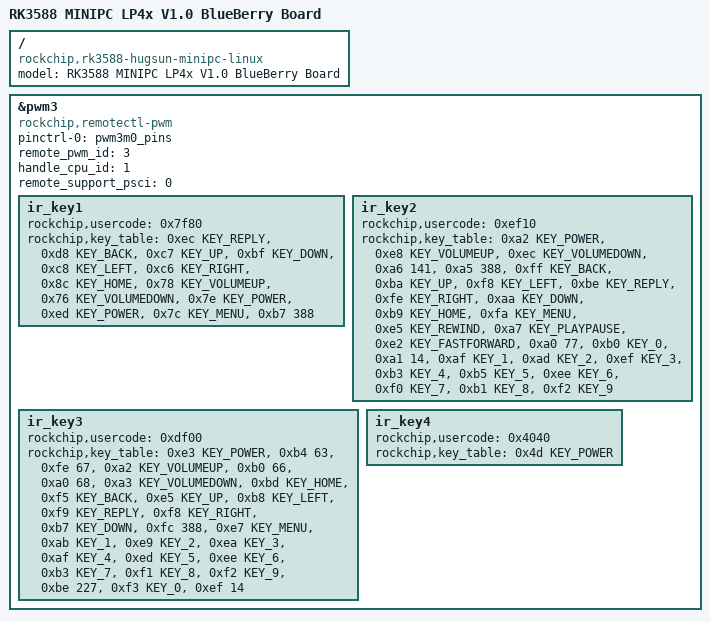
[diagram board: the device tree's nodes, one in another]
// SPDX-License-Identifier: (GPL-2.0+ OR MIT)
/*
 * Copyright (c) 2021 Rockchip Electronics Co., Ltd.
 *
 */

/dts-v1/;

#include "rk3588-blueberry-minipc.dtsi"
#include "rk3588-linux.dtsi"

/ {
	model = "RK3588 MINIPC LP4x V1.0 BlueBerry Board";
	compatible = "rockchip,rk3588-hugsun-minipc-linux", "rockchip,rk3588";
};

&pwm3 {
	compatible = "rockchip,remotectl-pwm";
	pinctrl-names = "default";
	pinctrl-0 = <&pwm3m0_pins>;
	remote_pwm_id = <3>;
	handle_cpu_id = <1>;
	remote_support_psci = <0>;
	status = "okay";

	ir_key1 {  //hugsun blue remote
		rockchip,usercode = <0x7f80>;
		rockchip,key_table =
			<0xec	KEY_REPLY>,
			<0xd8	KEY_BACK>,
			<0xc7	KEY_UP>,
			<0xbf	KEY_DOWN>,
			<0xc8	KEY_LEFT>,
			<0xc6	KEY_RIGHT>,
			<0x8c	KEY_HOME>,
			<0x78	KEY_VOLUMEUP>,
			<0x76	KEY_VOLUMEDOWN>,
			<0x7e	KEY_POWER>,
			<0xed	KEY_POWER>,  //20171123 
			<0x7c	KEY_MENU>,
			<0xb7	388>;
	};

	ir_key2 {   //hugsun 
		rockchip,usercode = <0xef10>;
		rockchip,key_table =
			<0xa2 KEY_POWER>,
			<0xe8 KEY_VOLUMEUP>,
			<0xec KEY_VOLUMEDOWN>,
			<0xa6 141>,//KEY_SETUP>,
			<0xa5 388>,
			<0xff KEY_BACK>,
			<0xba KEY_UP>,
			<0xf8 KEY_LEFT>,
			<0xbe KEY_REPLY>,
			<0xfe KEY_RIGHT>,
			<0xaa KEY_DOWN>,
			<0xb9 KEY_HOME>,
			<0xfa KEY_MENU>,
			<0xe5 KEY_REWIND>, 
			<0xa7 KEY_PLAYPAUSE>,
			<0xe2 KEY_FASTFORWARD>,
			<0xa0 77>,  //@
			<0xb0 KEY_0>,
			<0xa1 14>,
			<0xaf KEY_1>,
			<0xad KEY_2>,
			<0xef KEY_3>,
			<0xb3 KEY_4>,
			<0xb5 KEY_5>,
			<0xee KEY_6>,
			<0xf0 KEY_7>,
			<0xb1 KEY_8>,
			<0xf2	KEY_9>;
	};

	ir_key3 {
		rockchip,usercode = <0xdf00>;
		rockchip,key_table =
			<0xe3 KEY_POWER>,
			<0xb4 63>,	//youtube
			<0xfe 67>,	//Media Center
			<0xa2 KEY_VOLUMEUP>,
			<0xb0 66>,	//Netflix
			<0xa0 68>,	//SetupWizard
			<0xa3 KEY_VOLUMEDOWN>,
			
			<0xbd KEY_HOME>,
			<0xf5 KEY_BACK>,
			
			<0xe5 KEY_UP>,    
			<0xb8 KEY_LEFT>,  
			<0xf9 KEY_REPLY>, 
			<0xf8 KEY_RIGHT>, 
			<0xb7 KEY_DOWN>,  
			<0xfc 388>,
			<0xe7 KEY_MENU>,
			
			<0xab KEY_1>, 
			<0xe9 KEY_2>, 
			<0xea KEY_3>, 
			<0xaf KEY_4>, 
			<0xed KEY_5>, 
			<0xee KEY_6>, 
			<0xb3 KEY_7>, 
			<0xf1 KEY_8>, 
			<0xf2 KEY_9>,
			<0xbe 227>,  //Fn
			<0xf3 KEY_0>,
			<0xef 14>;

	};

	ir_key4{
		rockchip,usercode = <0x4040>;
		rockchip,key_table =
		<0x4d KEY_POWER>;     //power (for 2.4g)
	};
};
